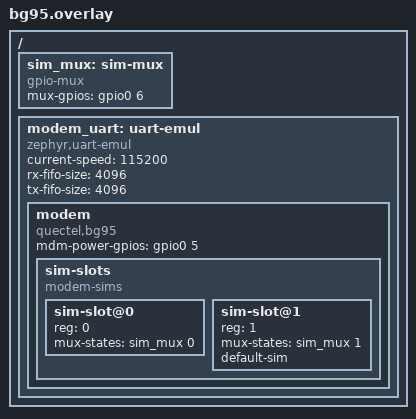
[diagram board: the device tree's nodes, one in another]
/*
 * Copyright (c) 2026 Pedro Ramos
 *
 * SPDX-License-Identifier: Apache-2.0
 *
 * A Quectel BG95 modem_cellular instance on an emulated UART, with one SIM
 * interface switched between two SIM slots by a gpio-mux on an emulated GPIO.
 */

#include <zephyr/dt-bindings/gpio/gpio.h>

/ {
	sim_mux: sim-mux {
		compatible = "gpio-mux";
		#mux-control-cells = <0>;
		#mux-state-cells = <1>;
		mux-gpios = <&gpio0 6 GPIO_ACTIVE_HIGH>;
	};

	modem_uart: uart-emul {
		compatible = "zephyr,uart-emul";
		current-speed = <115200>;
		rx-fifo-size = <4096>;
		tx-fifo-size = <4096>;
		status = "okay";

		modem: modem {
			compatible = "quectel,bg95";
			mdm-power-gpios = <&gpio0 5 GPIO_ACTIVE_HIGH>;
			status = "okay";

			sim-slots {
				compatible = "modem-sims";
				#address-cells = <1>;
				#size-cells = <0>;

				sim-slot@0 {
					reg = <0>;
					mux-states = <&sim_mux 0>;
				};

				sim-slot@1 {
					reg = <1>;
					mux-states = <&sim_mux 1>;
					default-sim;
				};
			};
		};
	};
};
